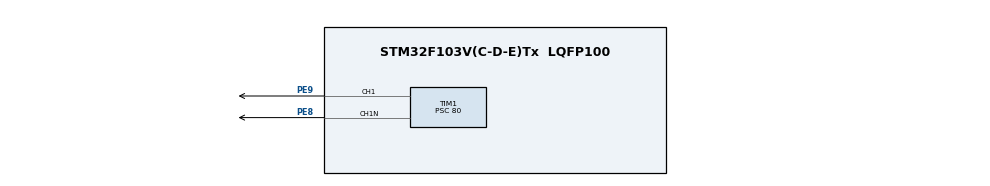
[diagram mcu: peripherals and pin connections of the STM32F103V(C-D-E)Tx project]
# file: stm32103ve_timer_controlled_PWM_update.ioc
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Mcu.Family=STM32F1
Mcu.Name=STM32F103V(C-D-E)Tx
Mcu.Package=LQFP100
NVIC.PriorityGroup=NVIC_PRIORITYGROUP_4
NVIC.TIM1_TRG_COM_IRQn=true\:0\:0\:false\:false\:true\:true
PE8.Mode=Output Compare1 CH1 CH1N
PE8.Signal=TIM1_CH1N
PE9.Signal=S_TIM1_CH1
ProjectManager.HeapSize=0x200
ProjectManager.StackSize=0x400
ProjectManager.TargetToolchain=MDK-ARM V5
RCC.APB1Freq_Value=8000000
RCC.APB2Freq_Value=8000000
SH.S_TIM1_CH1.0=TIM1_CH1,Output Compare1 CH1 CH1N
TIM1.AutoReloadPreload=TIM_AUTORELOAD_PRELOAD_ENABLE
TIM1.Channel-Output\ Compare1\ CH1\ CH1N=TIM_CHANNEL_1
TIM1.DeadTime=10
TIM1.OCMode_1=TIM_OCMODE_TIMING
TIM1.Period=100
TIM1.Prescaler=80
TIM2.AutoReloadPreload=TIM_AUTORELOAD_PRELOAD_DISABLE
TIM2.Channel-Output\ Compare1\ No\ Output=TIM_CHANNEL_1
TIM2.Period=200
TIM2.Prescaler=80
TIM2.Pulse-Output\ Compare1\ No\ Output=100
TIM2.TIM_MasterOutputTrigger=TIM_TRGO_RESET
TIM2.TIM_MasterSlaveMode=TIM_MASTERSLAVEMODE_ENABLE
VP_SYS_VS_ND.Mode=No_Debug
VP_TIM1_VS_ClockSourceINT.Mode=Internal
VP_TIM1_VS_ClockSourceITR.Mode=TriggerSource_ITR1
VP_TIM2_VS_ClockSourceINT.Mode=Internal
VP_TIM2_VS_no_output1.Mode=Output Compare1 No Output
board=stm32103ve_timer_controlled_PWM_update

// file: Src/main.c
/**
  ******************************************************************************
  * File Name          : main.c
  * Description        : Main program body
  ******************************************************************************
  ** This notice applies to any and all portions of this file
  * that are not between comment pairs USER CODE BEGIN and
  * USER CODE END. Other portions of this file, whether
  * inserted by the user or by software development tools
  * are owned by their respective copyright owners.
  *
  * COPYRIGHT(c) 2017 STMicroelectronics
  *
  * Redistribution and use in source and binary forms, with or without modification,
  * are permitted provided that the following conditions are met:
  *   1. Redistributions of source code must retain the above copyright notice,
  *      this list of conditions and the following disclaimer.
  *   2. Redistributions in binary form must reproduce the above copyright notice,
  *      this list of conditions and the following disclaimer in the documentation
  *      and/or other materials provided with the distribution.
  *   3. Neither the name of STMicroelectronics nor the names of its contributors
  *      may be used to endorse or promote products derived from this software
  *      without specific prior written permission.
  *
  * THIS SOFTWARE IS PROVIDED BY THE COPYRIGHT HOLDERS AND CONTRIBUTORS "AS IS"
  * AND ANY EXPRESS OR IMPLIED WARRANTIES, INCLUDING, BUT NOT LIMITED TO, THE
  * IMPLIED WARRANTIES OF MERCHANTABILITY AND FITNESS FOR A PARTICULAR PURPOSE ARE
  * DISCLAIMED. IN NO EVENT SHALL THE COPYRIGHT HOLDER OR CONTRIBUTORS BE LIABLE
  * FOR ANY DIRECT, INDIRECT, INCIDENTAL, SPECIAL, EXEMPLARY, OR CONSEQUENTIAL
  * DAMAGES (INCLUDING, BUT NOT LIMITED TO, PROCUREMENT OF SUBSTITUTE GOODS OR
  * SERVICES; LOSS OF USE, DATA, OR PROFITS; OR BUSINESS INTERRUPTION) HOWEVER
  * CAUSED AND ON ANY THEORY OF LIABILITY, WHETHER IN CONTRACT, STRICT LIABILITY,
  * OR TORT (INCLUDING NEGLIGENCE OR OTHERWISE) ARISING IN ANY WAY OUT OF THE USE
  * OF THIS SOFTWARE, EVEN IF ADVISED OF THE POSSIBILITY OF SUCH DAMAGE.
  *
  ******************************************************************************
  */

#include "main.h"
#include "stm32f1xx_hal.h"

TIM_HandleTypeDef htim1;
TIM_HandleTypeDef htim2;

/* USER CODE BEGIN PV */
/* Private variables ---------------------------------------------------------*/
uint16_t sequence;
uint16_t duty_cycle[] = {10, 20, 50, 60};
/* USER CODE END PV */

void SystemClock_Config(void);
static void MX_GPIO_Init(void);
static void MX_TIM1_Init(void);
static void MX_TIM2_Init(void);
void HAL_TIM_MspPostInit(TIM_HandleTypeDef *htim);

/* USER CODE BEGIN PFP */
/* Private function prototypes -----------------------------------------------*/

/* USER CODE END PFP */

int main(void)
{

  /* MCU Configuration----------------------------------------------------------*/

  /* Reset of all peripherals, Initializes the Flash interface and the Systick. */
  HAL_Init();

  /* Configure the system clock */
  SystemClock_Config();

  /* Initialize all configured peripherals */
  MX_GPIO_Init();
  MX_TIM1_Init();
  MX_TIM2_Init();

  /* USER CODE BEGIN 2 */
	sequence = 0;
	HAL_TIMEx_ConfigCommutationEvent_IT(&htim1, TIM_TS_ITR1, TIM_COMMUTATION_TRGI);
	TIM1->DIER |= TIM_DIER_TIE;
	HAL_TIM_Base_Start(&htim2);
	HAL_TIM_Base_Start(&htim1);
	HAL_TIM_GenerateEvent(&htim1, TIM_EGR_COMG);
  /* USER CODE END 2 */

  /* Infinite loop */
  while (1)
  {

  }

}

/** System Clock Configuration
*/
void SystemClock_Config(void)
{

  RCC_OscInitTypeDef RCC_OscInitStruct;
  RCC_ClkInitTypeDef RCC_ClkInitStruct;

    /**Initializes the CPU, AHB and APB busses clocks
    */
  RCC_OscInitStruct.OscillatorType = RCC_OSCILLATORTYPE_HSI;
  RCC_OscInitStruct.HSIState = RCC_HSI_ON;
  RCC_OscInitStruct.HSICalibrationValue = 16;
  RCC_OscInitStruct.PLL.PLLState = RCC_PLL_NONE;
  if (HAL_RCC_OscConfig(&RCC_OscInitStruct) != HAL_OK)
  {
    _Error_Handler(__FILE__, __LINE__);
  }

    /**Initializes the CPU, AHB and APB busses clocks
    */
  RCC_ClkInitStruct.ClockType = RCC_CLOCKTYPE_HCLK|RCC_CLOCKTYPE_SYSCLK
                              |RCC_CLOCKTYPE_PCLK1|RCC_CLOCKTYPE_PCLK2;
  RCC_ClkInitStruct.SYSCLKSource = RCC_SYSCLKSOURCE_HSI;
  RCC_ClkInitStruct.AHBCLKDivider = RCC_SYSCLK_DIV1;
  RCC_ClkInitStruct.APB1CLKDivider = RCC_HCLK_DIV1;
  RCC_ClkInitStruct.APB2CLKDivider = RCC_HCLK_DIV1;

  if (HAL_RCC_ClockConfig(&RCC_ClkInitStruct, FLASH_LATENCY_0) != HAL_OK)
  {
    _Error_Handler(__FILE__, __LINE__);
  }

    /**Configure the Systick interrupt time
    */
  HAL_SYSTICK_Config(HAL_RCC_GetHCLKFreq()/1000);

    /**Configure the Systick
    */
  HAL_SYSTICK_CLKSourceConfig(SYSTICK_CLKSOURCE_HCLK);

  /* SysTick_IRQn interrupt configuration */
  HAL_NVIC_SetPriority(SysTick_IRQn, 0, 0);
}

/* TIM1 init function */
static void MX_TIM1_Init(void)
{

  TIM_ClockConfigTypeDef sClockSourceConfig;
  TIM_SlaveConfigTypeDef sSlaveConfig;
  TIM_MasterConfigTypeDef sMasterConfig;
  TIM_OC_InitTypeDef sConfigOC;
  TIM_BreakDeadTimeConfigTypeDef sBreakDeadTimeConfig;

  htim1.Instance = TIM1;
  htim1.Init.Prescaler = 80;
  htim1.Init.CounterMode = TIM_COUNTERMODE_UP;
  htim1.Init.Period = 100;
  htim1.Init.ClockDivision = TIM_CLOCKDIVISION_DIV1;
  htim1.Init.RepetitionCounter = 0;
  htim1.Init.AutoReloadPreload = TIM_AUTORELOAD_PRELOAD_ENABLE;
  if (HAL_TIM_Base_Init(&htim1) != HAL_OK)
  {
    _Error_Handler(__FILE__, __LINE__);
  }

  sClockSourceConfig.ClockSource = TIM_CLOCKSOURCE_INTERNAL;
  if (HAL_TIM_ConfigClockSource(&htim1, &sClockSourceConfig) != HAL_OK)
  {
    _Error_Handler(__FILE__, __LINE__);
  }

  if (HAL_TIM_OC_Init(&htim1) != HAL_OK)
  {
    _Error_Handler(__FILE__, __LINE__);
  }

  sSlaveConfig.SlaveMode = TIM_SLAVEMODE_TRIGGER;
  sSlaveConfig.InputTrigger = TIM_TS_ITR1;
  if (HAL_TIM_SlaveConfigSynchronization(&htim1, &sSlaveConfig) != HAL_OK)
  {
    _Error_Handler(__FILE__, __LINE__);
  }

  sMasterConfig.MasterOutputTrigger = TIM_TRGO_RESET;
  sMasterConfig.MasterSlaveMode = TIM_MASTERSLAVEMODE_DISABLE;
  if (HAL_TIMEx_MasterConfigSynchronization(&htim1, &sMasterConfig) != HAL_OK)
  {
    _Error_Handler(__FILE__, __LINE__);
  }

  sConfigOC.OCMode = TIM_OCMODE_TIMING;
  sConfigOC.Pulse = 0;
  sConfigOC.OCPolarity = TIM_OCPOLARITY_HIGH;
  sConfigOC.OCNPolarity = TIM_OCNPOLARITY_HIGH;
  sConfigOC.OCFastMode = TIM_OCFAST_DISABLE;
  sConfigOC.OCIdleState = TIM_OCIDLESTATE_RESET;
  sConfigOC.OCNIdleState = TIM_OCNIDLESTATE_RESET;
  if (HAL_TIM_OC_ConfigChannel(&htim1, &sConfigOC, TIM_CHANNEL_1) != HAL_OK)
  {
    _Error_Handler(__FILE__, __LINE__);
  }

  sBreakDeadTimeConfig.OffStateRunMode = TIM_OSSR_DISABLE;
  sBreakDeadTimeConfig.OffStateIDLEMode = TIM_OSSI_DISABLE;
  sBreakDeadTimeConfig.LockLevel = TIM_LOCKLEVEL_OFF;
  sBreakDeadTimeConfig.DeadTime = 10;
  sBreakDeadTimeConfig.BreakState = TIM_BREAK_DISABLE;
  sBreakDeadTimeConfig.BreakPolarity = TIM_BREAKPOLARITY_HIGH;
  sBreakDeadTimeConfig.AutomaticOutput = TIM_AUTOMATICOUTPUT_DISABLE;
  if (HAL_TIMEx_ConfigBreakDeadTime(&htim1, &sBreakDeadTimeConfig) != HAL_OK)
  {
    _Error_Handler(__FILE__, __LINE__);
  }

  HAL_TIM_MspPostInit(&htim1);

}

/* TIM2 init function */
static void MX_TIM2_Init(void)
{

  TIM_ClockConfigTypeDef sClockSourceConfig;
  TIM_MasterConfigTypeDef sMasterConfig;
  TIM_OC_InitTypeDef sConfigOC;

  htim2.Instance = TIM2;
  htim2.Init.Prescaler = 80;
  htim2.Init.CounterMode = TIM_COUNTERMODE_UP;
  htim2.Init.Period = 200;
  htim2.Init.ClockDivision = TIM_CLOCKDIVISION_DIV1;
  htim2.Init.AutoReloadPreload = TIM_AUTORELOAD_PRELOAD_DISABLE;
  if (HAL_TIM_Base_Init(&htim2) != HAL_OK)
  {
    _Error_Handler(__FILE__, __LINE__);
  }

  sClockSourceConfig.ClockSource = TIM_CLOCKSOURCE_INTERNAL;
  if (HAL_TIM_ConfigClockSource(&htim2, &sClockSourceConfig) != HAL_OK)
  {
    _Error_Handler(__FILE__, __LINE__);
  }

  if (HAL_TIM_OC_Init(&htim2) != HAL_OK)
  {
    _Error_Handler(__FILE__, __LINE__);
  }

  sMasterConfig.MasterOutputTrigger = TIM_TRGO_OC1REF;
  sMasterConfig.MasterSlaveMode = TIM_MASTERSLAVEMODE_ENABLE;
  if (HAL_TIMEx_MasterConfigSynchronization(&htim2, &sMasterConfig) != HAL_OK)
  {
    _Error_Handler(__FILE__, __LINE__);
  }

  sConfigOC.OCMode = TIM_OCMODE_TIMING;
  sConfigOC.Pulse = 100;
  sConfigOC.OCPolarity = TIM_OCPOLARITY_HIGH;
  sConfigOC.OCFastMode = TIM_OCFAST_DISABLE;
  if (HAL_TIM_OC_ConfigChannel(&htim2, &sConfigOC, TIM_CHANNEL_1) != HAL_OK)
  {
    _Error_Handler(__FILE__, __LINE__);
  }

}

/** Pinout Configuration
*/
static void MX_GPIO_Init(void)
{

  /* GPIO Ports Clock Enable */
  __HAL_RCC_GPIOE_CLK_ENABLE();

}

/* USER CODE BEGIN 4 */
void HAL_TIMEx_CommutationCallback(TIM_HandleTypeDef *htim)
{
	TIM_OC_InitTypeDef sConfigOC;

	switch (sequence)
	{
		case 0:
			sConfigOC.OCMode = TIM_OCMODE_PWM1;
			sConfigOC.OCPolarity = TIM_OCPOLARITY_HIGH;
			sConfigOC.OCNPolarity = TIM_OCNPOLARITY_HIGH;
			HAL_TIM_OC_ConfigChannel(htim, &sConfigOC, TIM_CHANNEL_1);
			sequence++;
			break;

		case 1:
			__HAL_TIM_SET_COMPARE(htim, TIM_CHANNEL_1, duty_cycle[sequence-1]);
			sequence++;
			break;

		case 2:
			__HAL_TIM_SET_COMPARE(htim, TIM_CHANNEL_1, duty_cycle[sequence-1]);
			HAL_TIMEx_OCN_Stop(htim, TIM_CHANNEL_1);
			sequence++;
			break;

		case 3:
			__HAL_TIM_SET_COMPARE(htim, TIM_CHANNEL_1, duty_cycle[sequence-1]);
			HAL_TIM_OC_Stop(htim, TIM_CHANNEL_1);
			HAL_TIMEx_OCN_Start(htim, TIM_CHANNEL_1);
			sequence++;
			break;

		case 4:
			__HAL_TIM_SET_COMPARE(htim, TIM_CHANNEL_1, duty_cycle[sequence-1]);
			HAL_TIM_OC_Start(htim, TIM_CHANNEL_1);
			sequence++;
			break;

		default:
			sequence = 1;
	}

}
/* USER CODE END 4 */

void _Error_Handler(char * file, int line)
{
  while(1)
  {
  }
}

/************************ (C) COPYRIGHT STMicroelectronics *****END OF FILE****/
